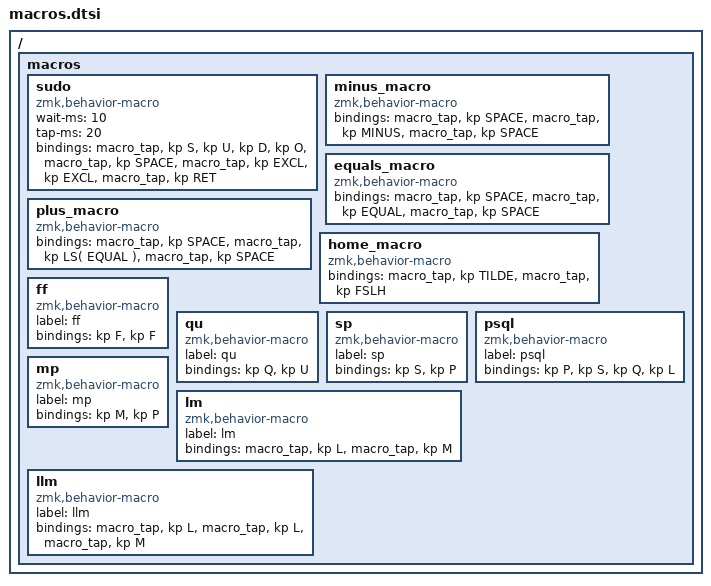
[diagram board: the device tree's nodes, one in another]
/ {
    macros {
        sudo: sudo { // SUDO_BANG_BANG
            compatible = "zmk,behavior-macro";
            #binding-cells = <0>;
            wait-ms = <10>;
            tap-ms = <20>;
            bindings
                = <&macro_tap &kp S &kp U &kp D &kp O>  // "sudo"
                , <&macro_tap &kp SPACE>                // space
                , <&macro_tap &kp EXCL &kp EXCL>        // "!!"
                , <&macro_tap &kp RET>                  // Enter key
                ;
        };

        minus_macro: minus_macro {
            compatible = "zmk,behavior-macro";
            #binding-cells = <0>;
            bindings
                = <&macro_tap &kp SPACE>
                , <&macro_tap &kp MINUS>
                , <&macro_tap &kp SPACE>
                ;
        };

        equals_macro: equals_macro {
            compatible = "zmk,behavior-macro";
            #binding-cells = <0>;
            bindings
                = <&macro_tap &kp SPACE>
                , <&macro_tap &kp EQUAL>
                , <&macro_tap &kp SPACE>
                ;
        };
        plus_macro: plus_macro {
            compatible = "zmk,behavior-macro";
            #binding-cells = <0>;
            bindings
                = <&macro_tap &kp SPACE>
                , <&macro_tap &kp LS( EQUAL )>
                , <&macro_tap &kp SPACE>
                ;
        };
        home_macro: home_macro {
            compatible = "zmk,behavior-macro";
            #binding-cells = <0>;
            bindings
                = <&macro_tap &kp TILDE>
                , <&macro_tap &kp FSLH>
                ;
        };
		    ff: ff {
            label = "ff";
            compatible = "zmk,behavior-macro";
            #binding-cells = <0>;
            bindings = <&kp F &kp F>;
        };
        qu: qu {
            label = "qu";
            compatible = "zmk,behavior-macro";
            #binding-cells = <0>;
            bindings = <&kp Q &kp U>;
        };
        sp: sp {
            label = "sp";
            compatible = "zmk,behavior-macro";
            #binding-cells = <0>;
            bindings = <&kp S &kp P>;
        };

        psql: psql {
            label = "psql";
            compatible = "zmk,behavior-macro";
            #binding-cells = <0>;
            bindings = <&kp P &kp S &kp Q &kp L>;
        };
				mp: mp {
            label = "mp";
            compatible = "zmk,behavior-macro";
            #binding-cells = <0>;
            bindings = <&kp M &kp P>;
        };
        lm: lm {
            label = "lm";
            compatible = "zmk,behavior-macro";
            #binding-cells = <0>;
            bindings =
                <&macro_tap &kp L>,
                <&macro_tap &kp M>;
        };
        llm: llm {
            label = "llm";
            compatible = "zmk,behavior-macro";
            #binding-cells = <0>;
            bindings =
                <&macro_tap &kp L>,
                <&macro_tap &kp L>,
                <&macro_tap &kp M>;
        };
    };
};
